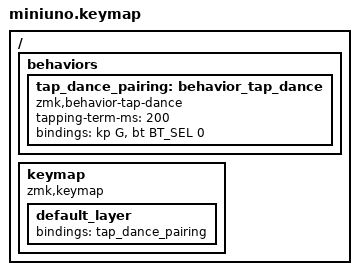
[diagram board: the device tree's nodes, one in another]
#include <behaviors.dtsi>
#include <dt-bindings/zmk/keys.h>
#include <dt-bindings/zmk/bt.h>

/ {
  behaviors {
    tap_dance_pairing: behavior_tap_dance {
      compatible = "zmk,behavior-tap-dance";
      #binding-cells = <0>;
      tapping-term-ms = <200>;
      bindings = <&kp G>, <&bt BT_SEL 0>;
    };
  };

  keymap {
    compatible = "zmk,keymap";

    default_layer {
      bindings = <
        &tap_dance_pairing
      >;
    };
  };
};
